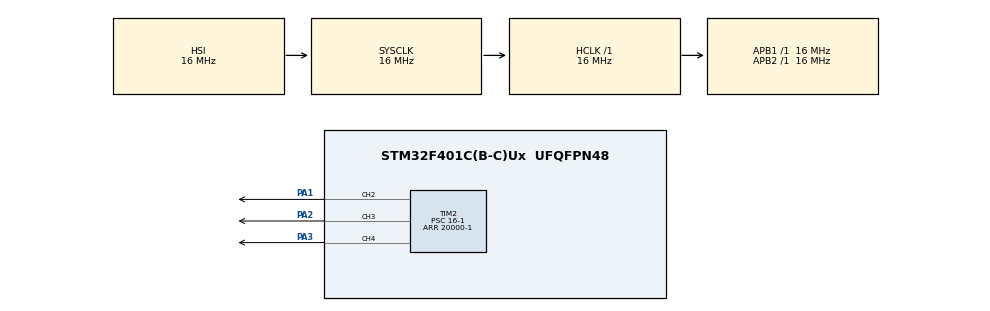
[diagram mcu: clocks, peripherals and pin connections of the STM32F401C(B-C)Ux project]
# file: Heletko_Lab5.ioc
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Mcu.Family=STM32F4
Mcu.Name=STM32F401C(B-C)Ux
Mcu.Package=UFQFPN48
NVIC.PriorityGroup=NVIC_PRIORITYGROUP_4
NVIC.TIM3_IRQn=true\:0\:0\:false\:true\:true\:1\:true\:true\:true
NVIC.TIM4_IRQn=true\:0\:0\:false\:true\:true\:2\:true\:true\:true
PA1.Signal=S_TIM2_CH2
PA2.Signal=S_TIM2_CH3
PA3.Signal=S_TIM2_CH4
ProjectManager.HeapSize=0x200
ProjectManager.StackSize=0x400
ProjectManager.TargetToolchain=STM32CubeIDE
RCC.AHBFreq_Value=16000000
RCC.APB1Freq_Value=16000000
RCC.APB2Freq_Value=16000000
RCC.CortexFreq_Value=16000000
RCC.HSE_VALUE=25000000
RCC.HSI_VALUE=16000000
RCC.LSE_VALUE=32768
RCC.SYSCLKFreq_VALUE=16000000
RCC.VCOOutputFreq_Value=192000000
SH.S_TIM2_CH2.0=TIM2_CH2,PWM Generation2 CH2
SH.S_TIM2_CH3.0=TIM2_CH3,PWM Generation3 CH3
SH.S_TIM2_CH4.0=TIM2_CH4,PWM Generation4 CH4
TIM2.Channel-PWM\ Generation2\ CH2=TIM_CHANNEL_2
TIM2.Channel-PWM\ Generation3\ CH3=TIM_CHANNEL_3
TIM2.Channel-PWM\ Generation4\ CH4=TIM_CHANNEL_4
TIM2.Period=20000-1
TIM2.Prescaler=16-1
TIM2.Pulse-PWM\ Generation2\ CH2=1500
TIM2.Pulse-PWM\ Generation3\ CH3=1500
TIM2.Pulse-PWM\ Generation4\ CH4=1500
TIM3.Period=20
TIM3.Prescaler=16000
TIM4.Period=10
TIM4.Prescaler=16000
VP_TIM2_VS_ClockSourceINT.Mode=Internal
VP_TIM3_VS_ClockSourceINT.Mode=Internal
VP_TIM4_VS_ClockSourceINT.Mode=Internal
board=custom

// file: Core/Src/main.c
/* USER CODE BEGIN Header */
/**
  ******************************************************************************
  * @file           : main.c
  * @brief          : Main program body
  ******************************************************************************
  * @attention
  *
  * Copyright (c) 2022 STMicroelectronics.
  * All rights reserved.
  *
  * This software is licensed under terms that can be found in the LICENSE file
  * in the root directory of this software component.
  * If no LICENSE file comes with this software, it is provided AS-IS.
  *
  ******************************************************************************
  */
/* USER CODE END Header */
#include "main.h"

TIM_HandleTypeDef htim2;
TIM_HandleTypeDef htim3;
TIM_HandleTypeDef htim4;

void SystemClock_Config(void);
static void MX_GPIO_Init(void);
static void MX_TIM2_Init(void);
static void MX_TIM3_Init(void);
static void MX_TIM4_Init(void);
static void MX_NVIC_Init(void);

/* USER CODE BEGIN 0 */
int PWidth1 = 1500;
int PWidth2 = 1500;
int direction1 = 0;
int direction2 = 0;
/* USER CODE END 0 */

int main(void)
{

  /* MCU Configuration--------------------------------------------------------*/

  /* Reset of all peripherals, Initializes the Flash interface and the Systick. */
  HAL_Init();

  /* Configure the system clock */
  SystemClock_Config();

  /* Initialize all configured peripherals */
  MX_GPIO_Init();
  MX_TIM2_Init();
  MX_TIM3_Init();
  MX_TIM4_Init();

  /* Initialize interrupts */
  MX_NVIC_Init();
  /* USER CODE BEGIN 2 */
  HAL_TIM_PWM_Start(&htim2, TIM_CHANNEL_2);
  HAL_TIM_PWM_Start(&htim2, TIM_CHANNEL_3);
  HAL_TIM_PWM_Start(&htim2, TIM_CHANNEL_4);
  HAL_TIM_Base_Start_IT(&htim3);
  HAL_TIM_Base_Start_IT(&htim4);
  /* USER CODE END 2 */

  /* Infinite loop */
  while (1)
  {

  }
}

void SystemClock_Config(void)
{
  RCC_OscInitTypeDef RCC_OscInitStruct = {0};
  RCC_ClkInitTypeDef RCC_ClkInitStruct = {0};

  /** Configure the main internal regulator output voltage
  */
  __HAL_RCC_PWR_CLK_ENABLE();
  __HAL_PWR_VOLTAGESCALING_CONFIG(PWR_REGULATOR_VOLTAGE_SCALE2);

  /** Initializes the RCC Oscillators according to the specified parameters
  * in the RCC_OscInitTypeDef structure.
  */
  RCC_OscInitStruct.OscillatorType = RCC_OSCILLATORTYPE_HSI;
  RCC_OscInitStruct.HSIState = RCC_HSI_ON;
  RCC_OscInitStruct.HSICalibrationValue = RCC_HSICALIBRATION_DEFAULT;
  RCC_OscInitStruct.PLL.PLLState = RCC_PLL_NONE;
  if (HAL_RCC_OscConfig(&RCC_OscInitStruct) != HAL_OK)
  {
    Error_Handler();
  }

  /** Initializes the CPU, AHB and APB buses clocks
  */
  RCC_ClkInitStruct.ClockType = RCC_CLOCKTYPE_HCLK|RCC_CLOCKTYPE_SYSCLK
                              |RCC_CLOCKTYPE_PCLK1|RCC_CLOCKTYPE_PCLK2;
  RCC_ClkInitStruct.SYSCLKSource = RCC_SYSCLKSOURCE_HSI;
  RCC_ClkInitStruct.AHBCLKDivider = RCC_SYSCLK_DIV1;
  RCC_ClkInitStruct.APB1CLKDivider = RCC_HCLK_DIV1;
  RCC_ClkInitStruct.APB2CLKDivider = RCC_HCLK_DIV1;

  if (HAL_RCC_ClockConfig(&RCC_ClkInitStruct, FLASH_LATENCY_0) != HAL_OK)
  {
    Error_Handler();
  }
}

/**
  * @brief NVIC Configuration.
  * @retval None
  */
static void MX_NVIC_Init(void)
{
  /* TIM3_IRQn interrupt configuration */
  HAL_NVIC_SetPriority(TIM3_IRQn, 0, 0);
  HAL_NVIC_EnableIRQ(TIM3_IRQn);
  /* TIM4_IRQn interrupt configuration */
  HAL_NVIC_SetPriority(TIM4_IRQn, 0, 0);
  HAL_NVIC_EnableIRQ(TIM4_IRQn);
}

static void MX_TIM2_Init(void)
{

  TIM_ClockConfigTypeDef sClockSourceConfig = {0};
  TIM_MasterConfigTypeDef sMasterConfig = {0};
  TIM_OC_InitTypeDef sConfigOC = {0};

  htim2.Instance = TIM2;
  htim2.Init.Prescaler = 16-1;
  htim2.Init.CounterMode = TIM_COUNTERMODE_UP;
  htim2.Init.Period = 20000-1;
  htim2.Init.ClockDivision = TIM_CLOCKDIVISION_DIV1;
  htim2.Init.AutoReloadPreload = TIM_AUTORELOAD_PRELOAD_DISABLE;
  if (HAL_TIM_Base_Init(&htim2) != HAL_OK)
  {
    Error_Handler();
  }
  sClockSourceConfig.ClockSource = TIM_CLOCKSOURCE_INTERNAL;
  if (HAL_TIM_ConfigClockSource(&htim2, &sClockSourceConfig) != HAL_OK)
  {
    Error_Handler();
  }
  if (HAL_TIM_PWM_Init(&htim2) != HAL_OK)
  {
    Error_Handler();
  }
  sMasterConfig.MasterOutputTrigger = TIM_TRGO_RESET;
  sMasterConfig.MasterSlaveMode = TIM_MASTERSLAVEMODE_DISABLE;
  if (HAL_TIMEx_MasterConfigSynchronization(&htim2, &sMasterConfig) != HAL_OK)
  {
    Error_Handler();
  }
  sConfigOC.OCMode = TIM_OCMODE_PWM1;
  sConfigOC.Pulse = 1500;
  sConfigOC.OCPolarity = TIM_OCPOLARITY_HIGH;
  sConfigOC.OCFastMode = TIM_OCFAST_DISABLE;
  if (HAL_TIM_PWM_ConfigChannel(&htim2, &sConfigOC, TIM_CHANNEL_2) != HAL_OK)
  {
    Error_Handler();
  }
  if (HAL_TIM_PWM_ConfigChannel(&htim2, &sConfigOC, TIM_CHANNEL_3) != HAL_OK)
  {
    Error_Handler();
  }
  if (HAL_TIM_PWM_ConfigChannel(&htim2, &sConfigOC, TIM_CHANNEL_4) != HAL_OK)
  {
    Error_Handler();
  }
  HAL_TIM_MspPostInit(&htim2);

}

static void MX_TIM3_Init(void)
{

  TIM_ClockConfigTypeDef sClockSourceConfig = {0};
  TIM_MasterConfigTypeDef sMasterConfig = {0};

  htim3.Instance = TIM3;
  htim3.Init.Prescaler = 16000;
  htim3.Init.CounterMode = TIM_COUNTERMODE_UP;
  htim3.Init.Period = 20;
  htim3.Init.ClockDivision = TIM_CLOCKDIVISION_DIV1;
  htim3.Init.AutoReloadPreload = TIM_AUTORELOAD_PRELOAD_DISABLE;
  if (HAL_TIM_Base_Init(&htim3) != HAL_OK)
  {
    Error_Handler();
  }
  sClockSourceConfig.ClockSource = TIM_CLOCKSOURCE_INTERNAL;
  if (HAL_TIM_ConfigClockSource(&htim3, &sClockSourceConfig) != HAL_OK)
  {
    Error_Handler();
  }
  sMasterConfig.MasterOutputTrigger = TIM_TRGO_RESET;
  sMasterConfig.MasterSlaveMode = TIM_MASTERSLAVEMODE_DISABLE;
  if (HAL_TIMEx_MasterConfigSynchronization(&htim3, &sMasterConfig) != HAL_OK)
  {
    Error_Handler();
  }

}

static void MX_TIM4_Init(void)
{

  TIM_ClockConfigTypeDef sClockSourceConfig = {0};
  TIM_MasterConfigTypeDef sMasterConfig = {0};

  htim4.Instance = TIM4;
  htim4.Init.Prescaler = 16000;
  htim4.Init.CounterMode = TIM_COUNTERMODE_UP;
  htim4.Init.Period = 10;
  htim4.Init.ClockDivision = TIM_CLOCKDIVISION_DIV1;
  htim4.Init.AutoReloadPreload = TIM_AUTORELOAD_PRELOAD_DISABLE;
  if (HAL_TIM_Base_Init(&htim4) != HAL_OK)
  {
    Error_Handler();
  }
  sClockSourceConfig.ClockSource = TIM_CLOCKSOURCE_INTERNAL;
  if (HAL_TIM_ConfigClockSource(&htim4, &sClockSourceConfig) != HAL_OK)
  {
    Error_Handler();
  }
  sMasterConfig.MasterOutputTrigger = TIM_TRGO_RESET;
  sMasterConfig.MasterSlaveMode = TIM_MASTERSLAVEMODE_DISABLE;
  if (HAL_TIMEx_MasterConfigSynchronization(&htim4, &sMasterConfig) != HAL_OK)
  {
    Error_Handler();
  }

}

static void MX_GPIO_Init(void)
{

  /* GPIO Ports Clock Enable */
  __HAL_RCC_GPIOA_CLK_ENABLE();

}

/* USER CODE BEGIN 4 */
void HAL_TIM_PeriodElapsedCallback(TIM_HandleTypeDef *htim)
{
	if(htim->Instance == TIM3)
	{
		if(direction1 != 1)
		{
			if(PWidth1 < 2500) { PWidth1 += 5; __HAL_TIM_SetCompare(&htim2, TIM_CHANNEL_2, PWidth1); }
			else direction1 = 1;
		}
		else
		{
			if(PWidth1 > 500) { PWidth1 -= 5; __HAL_TIM_SetCompare(&htim2, TIM_CHANNEL_2, PWidth1); }
			else direction1 = 0;
		}
	}
	if(htim->Instance == TIM4)
	{
		if(direction2 != 1)
		{
			if(PWidth2 < 2500) { PWidth2 += 5;	__HAL_TIM_SetCompare(&htim2, TIM_CHANNEL_3, PWidth2); }
			else direction2 = 1;
		}
		else
		{
			if(PWidth2 > 500) { PWidth2 -= 5; __HAL_TIM_SetCompare(&htim2, TIM_CHANNEL_3, PWidth2); }
			else direction2 = 0;
		}
	}
}
/* USER CODE END 4 */

void Error_Handler(void)
{
  __disable_irq();
  while (1)
  {
  }
}
